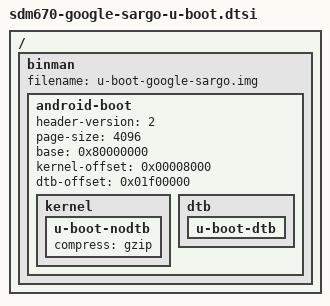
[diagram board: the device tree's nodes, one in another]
// SPDX-License-Identifier: GPL-2.0

#include <config.h>

/ {
	binman {
		filename = "u-boot-google-sargo.img";

		android-boot {
			header-version = <2>;
			page-size = <4096>;
			base = <0x80000000>;
			kernel-offset = <0x00008000>;
			dtb-offset = <0x01f00000>;

			kernel {
				u-boot-nodtb {
					compress = "gzip";
				};
			};

			dtb {
				u-boot-dtb {};
			};
		};
	};
};
